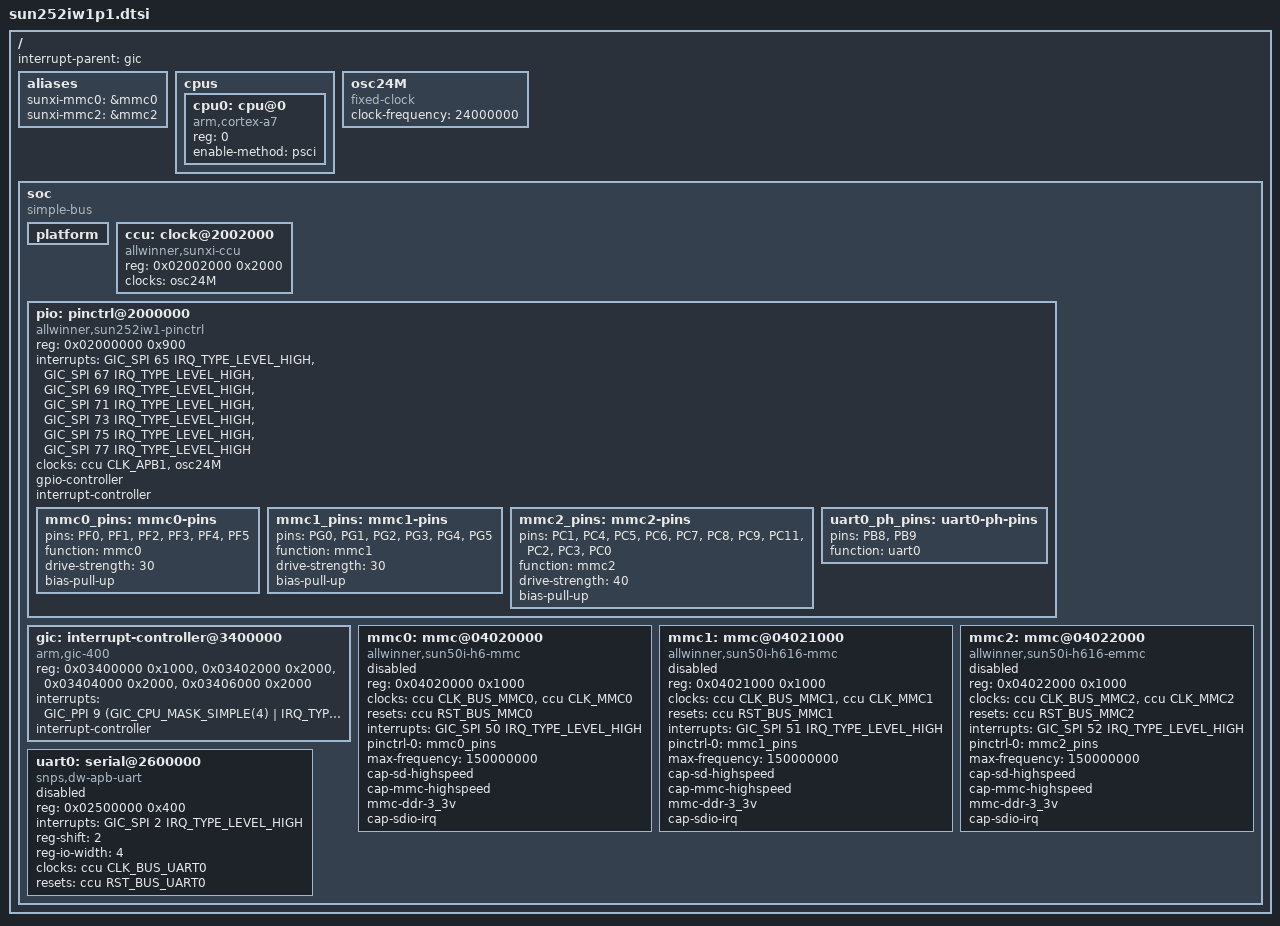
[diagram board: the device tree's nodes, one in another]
// SPDX-License-Identifier: (GPL-2.0+ OR MIT)
// Copyright (C) 2020 Arm Ltd.
// based on the H6 dtsi, which is:
//   Copyright (C) 2017 Icenowy Zheng <icenowy@aosc.io>

#include <dt-bindings/interrupt-controller/arm-gic.h>
#include <dt-bindings/clock/sun252iw1p1-ccu.h>
#include <dt-bindings/reset/sun252iw1p1-ccu.h>
#include <dt-bindings/gpio/gpio.h>

/ {
	interrupt-parent = <&gic>;
	#address-cells = <2>;
	#size-cells = <2>;

	aliases {
		sunxi-mmc0 = &mmc0;
		sunxi-mmc2 = &mmc2;
	};

	cpus {
		#address-cells = <1>;
		#size-cells = <0>;

		cpu0: cpu@0 {
			compatible = "arm,cortex-a7";
			device_type = "cpu";
			reg = <0>;
			enable-method = "psci";
		};
	};

	osc24M: osc24M {
		#clock-cells = <0>;
		compatible = "fixed-clock";
		clock-frequency = <24000000>;
	};

	soc {
		compatible = "simple-bus";
		#address-cells = <1>;
		#size-cells = <1>;
		ranges = <0x0 0x0 0x0 0x40000000>;

		platform:platform {
			device_type = "platform";
		};

		ccu: clock@2002000 {
			compatible = "allwinner,sunxi-ccu";
			reg = <0x02002000 0x2000>;
			clocks = <&osc24M>;
			clock-names = "hosc", "losc", "iosc";
			#clock-cells = <1>;
			#reset-cells = <1>;
		};

		pio: pinctrl@2000000{
			compatible = "allwinner,sun252iw1-pinctrl";
			reg = <0x02000000 0x900>;
			interrupts = <GIC_SPI 65 IRQ_TYPE_LEVEL_HIGH>,
				     <GIC_SPI 67 IRQ_TYPE_LEVEL_HIGH>,
				     <GIC_SPI 69 IRQ_TYPE_LEVEL_HIGH>,
				     <GIC_SPI 71 IRQ_TYPE_LEVEL_HIGH>,
				     <GIC_SPI 73 IRQ_TYPE_LEVEL_HIGH>,
				     <GIC_SPI 75 IRQ_TYPE_LEVEL_HIGH>,
				     <GIC_SPI 77 IRQ_TYPE_LEVEL_HIGH>;
			clocks = <&ccu CLK_APB1>, <&osc24M>;
			clock-names = "apb", "hosc";
			gpio-controller;
			#gpio-cells = <3>;
			interrupt-controller;
			#interrupt-cells = <3>;

			mmc0_pins: mmc0-pins {
				pins = "PF0", "PF1", "PF2", "PF3",
				       "PF4", "PF5";
				function = "mmc0";
				drive-strength = <30>;
				bias-pull-up;
			};

			/omit-if-no-ref/
			mmc1_pins: mmc1-pins {
				pins = "PG0", "PG1", "PG2", "PG3",
				       "PG4", "PG5";
				function = "mmc1";
				drive-strength = <30>;
				bias-pull-up;
			};

			mmc2_pins: mmc2-pins {
				pins = "PC1", "PC4", "PC5", "PC6",
					"PC7", "PC8", "PC9",
					"PC11", "PC2", "PC3", "PC0";
				function = "mmc2";
				drive-strength = <40>;
				bias-pull-up;
			};

			uart0_ph_pins: uart0-ph-pins {
				pins = "PB8", "PB9";
				function = "uart0";
			};
		};

		gic: interrupt-controller@3400000 {
			compatible = "arm,gic-400";
			reg = <0x03400000 0x1000>,
			      <0x03402000 0x2000>,
			      <0x03404000 0x2000>,
			      <0x03406000 0x2000>;
			interrupts = <GIC_PPI 9 (GIC_CPU_MASK_SIMPLE(4) | IRQ_TYPE_LEVEL_HIGH)>;
			interrupt-controller;
			#interrupt-cells = <3>;
		};

		mmc0: mmc@04020000 {
			compatible = "allwinner,sun50i-h6-mmc";
			reg = <0x04020000 0x1000>;
			clocks = <&ccu CLK_BUS_MMC0>, <&ccu CLK_MMC0>;
			clock-names = "ahb", "mmc";
			resets = <&ccu RST_BUS_MMC0>;
			reset-names = "ahb";
			interrupts = <GIC_SPI 50 IRQ_TYPE_LEVEL_HIGH>;
			pinctrl-names = "default";
			pinctrl-0 = <&mmc0_pins>;
			status = "disabled";
			max-frequency = <150000000>;
			cap-sd-highspeed;
			cap-mmc-highspeed;
			mmc-ddr-3_3v;
			cap-sdio-irq;
			#address-cells = <1>;
			#size-cells = <0>;
		};

		mmc1: mmc@04021000 {
			compatible = "allwinner,sun50i-h616-mmc",
				     "allwinner,sun50i-a100-mmc";
			reg = <0x04021000 0x1000>;
			clocks = <&ccu CLK_BUS_MMC1>, <&ccu CLK_MMC1>;
			clock-names = "ahb", "mmc";
			resets = <&ccu RST_BUS_MMC1>;
			reset-names = "ahb";
			interrupts = <GIC_SPI 51 IRQ_TYPE_LEVEL_HIGH>;
			pinctrl-names = "default";
			pinctrl-0 = <&mmc1_pins>;
			status = "disabled";
			max-frequency = <150000000>;
			cap-sd-highspeed;
			cap-mmc-highspeed;
			mmc-ddr-3_3v;
			cap-sdio-irq;
			#address-cells = <1>;
			#size-cells = <0>;
		};

		mmc2: mmc@04022000 {
			compatible = "allwinner,sun50i-h616-emmc",
				     "allwinner,sun50i-a100-emmc";
			reg = <0x04022000 0x1000>;
			clocks = <&ccu CLK_BUS_MMC2>, <&ccu CLK_MMC2>;
			clock-names = "ahb", "mmc";
			resets = <&ccu RST_BUS_MMC2>;
			reset-names = "rst";
			interrupts = <GIC_SPI 52 IRQ_TYPE_LEVEL_HIGH>;
			pinctrl-names = "default";
			pinctrl-0 = <&mmc2_pins>;
			status = "disabled";
			max-frequency = <150000000>;
			cap-sd-highspeed;
			cap-mmc-highspeed;
			mmc-ddr-3_3v;
			cap-sdio-irq;
			#address-cells = <1>;
			#size-cells = <0>;
		};

		uart0: serial@2600000 {
			compatible = "snps,dw-apb-uart";
			reg = <0x02500000 0x400>;
			interrupts = <GIC_SPI 2 IRQ_TYPE_LEVEL_HIGH>;
			reg-shift = <2>;
			reg-io-width = <4>;
			clocks = <&ccu CLK_BUS_UART0>;
			resets = <&ccu RST_BUS_UART0>;
			status = "disabled";
		};
	};
};
